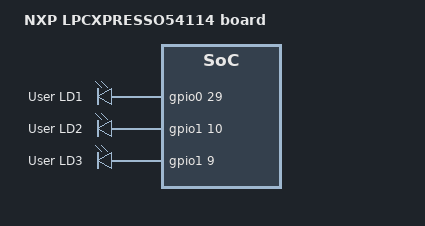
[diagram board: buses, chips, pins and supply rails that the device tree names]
/*
 * Copyright (c) 2017, NXP
 *
 * SPDX-License-Identifier: Apache-2.0
 */

/dts-v1/;

#include <nxp/nxp_lpc54xxx_m0.dtsi>

/ {
	model = "NXP LPCXPRESSO54114 board";
	compatible = "nxp,lpc54xxx","nxp,lpc";

	aliases {
		usart-0 = &usart0;
		mailbox-0 = &mailbox0;
		led0 = &red_led;
		led1 = &green_led;
		led2 = &blue_led;
	};

	chosen {
		zephyr,sram = &sram2;
		zephyr,flash = &sram1;
		/*zephyr,console = &usart0; uncomment to use console on M0  */
	};

	leds {
		compatible = "gpio-leds";
		red_led: led_0 {
			gpios = <&gpio0 29 0>;
			label = "User LD1";
		};
		green_led: led_1 {
			gpios = <&gpio1 10 0>;
			label = "User LD2";
		};
		blue_led: led_2 {
			gpios = <&gpio1 9 0>;
			label = "User LD3";
		};
	};
};

&usart0 {
	status = "disabled"; /* enable for console, if needed */
	current-speed = <115200>;
};

&mailbox0 {
	status = "ok";
};
